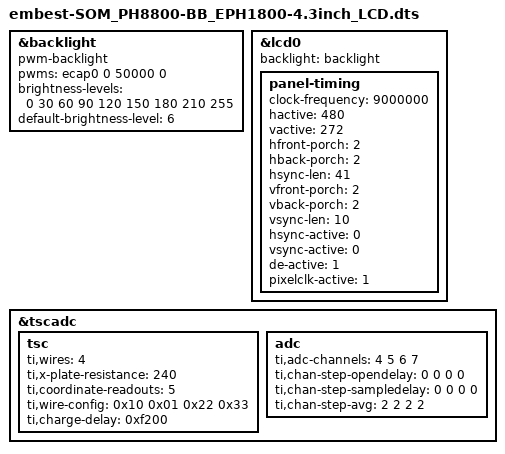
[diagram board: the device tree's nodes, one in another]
/*
 * Copyright (C) 2015 Embest Technology Co., Ltd., - http://www.embest-tech.com
 *
 * This program is free software; you can redistribute it and/or modify
 * it under the terms of the GNU General Public License version 2 as
 * published by the Free Software Foundation.
 *
 * This dts is for embest own product:
 * SOM-PH8800 + BB-EPH1800
 */
/*/dts-v1/;*/

#include "embest-SOM_PH8800-BB_EPH1800.dts"

&backlight {
	compatible = "pwm-backlight";

	pwms = <&ecap0 0 50000 0>;
	brightness-levels = <0 30 60 90 120 150 180 210 255>;
	default-brightness-level = <6>;
};

&lcd0{
	backlight = <&backlight>;
	panel-timing {
		/*This is the timing for 4.3inch lcd*/
		clock-frequency = <9000000>;
		hactive = <480>;
		vactive = <272>;
		hfront-porch = <2>;
		hback-porch = <2>;
		hsync-len = <41>;
		vfront-porch = <2>;
		vback-porch = <2>;
		vsync-len = <10>;
		hsync-active = <0>;
		vsync-active = <0>;
		de-active = <1>;
		pixelclk-active = <1>;
	};
};

&tscadc {
	status = "okay";

	tsc {
		ti,wires = <4>;
		ti,x-plate-resistance = <240>;
		ti,coordinate-readouts = <5>;
		ti,wire-config = <0x10 0x01 0x22 0x33>;
		ti,charge-delay = <0xf200>;
	};

	adc { 
		ti,adc-channels = <4 5 6 7>;
		ti,chan-step-opendelay = <0 0 0 0>;
		ti,chan-step-sampledelay = <0 0 0 0>;
		ti,chan-step-avg = <2 2 2 2>; 
	};
};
